# SPGSS2_1.0 register map
Vendor: Texas Instruments
Registers are 32-bit, read-write, no defined reset value unless marked. A register's access mark holds for its fields unless they carry their own. Offsets are as the file gives them; [hi:lo] are bit positions; lines under a group give offsets from that group; {n}, {i} and the like mark numbered series; 'fields as' and 'values as' point back to an identical list; <NAME> marks a mode.

## SPGSS2 (part 4 of 4)
0x47020 SPGSS2_UC3_I2CT_IPSTANDARD_CPU_INT group
  0x00 SPGSS2_UC3_I2CT_IPSTANDARD_IIDX ro — Interrupt index
    [7:0] STAT — I2C Module Interrupt Vector Value. This register provides the highes priority interrupt index. A read clears the corresponding interrupt flag in RIS and MISC. 15h-1Fh = Reserved
      0=NO_INTR (No interrupt pending); 1=RXDONEFG (Receive Done Flag); 2=TXDONEFG (Transmit Done Flag); 3=RXTRG (receive FIFO Trigger Level); 4=TXTRG (transmit FIFO Trigger level); 5=RXFULL (RX FIFO FULL Event/interrupt pending); 6=TXEMPTY (Transmit FIFO/Buffer Empty Event/interrupt pending); 7=TX_UNFL (Target TX FIFO underflow); 8=RX_OVFL (Target RX FIFO overflow event); 9=GENCALL (General Call Event); 10=STARTFG (Start Event); 11=STOPFG (Stop Event); 12=PEC_RX_ERR (PEC receive error event); 13=TIMEOUTA (Timeout A Event); 14=TIMEOUTB (Timeout B Event); 16=DMA_DONE_RX (DMA DONE on Channel RX); 17=DMA_DONE_TX (DMA DONE on Channel TX); 18=ARBLOSTFG (Arbitration Lost); 19=DMA_PREIRQ_RX (DMA PRE IRQ INTERRUPT); 20=DMA_PREIRQ_TX (DMA PRE IRQ INTERRUPT)
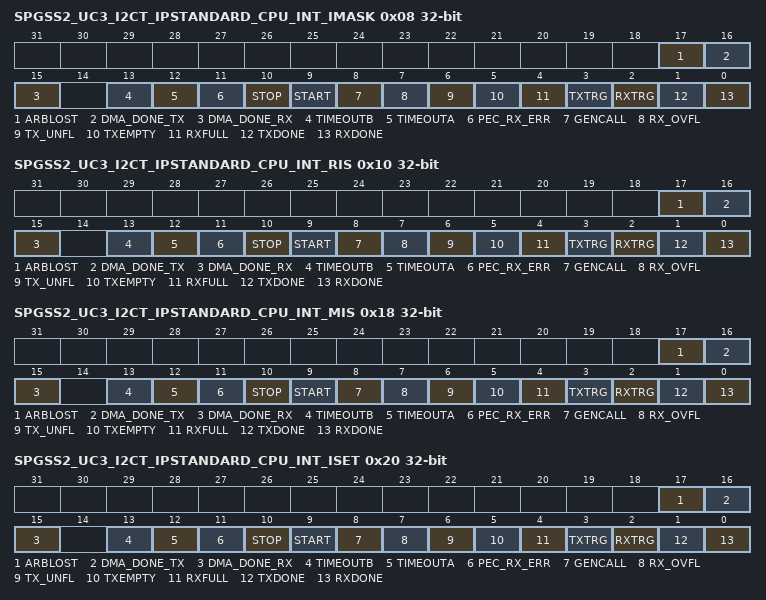
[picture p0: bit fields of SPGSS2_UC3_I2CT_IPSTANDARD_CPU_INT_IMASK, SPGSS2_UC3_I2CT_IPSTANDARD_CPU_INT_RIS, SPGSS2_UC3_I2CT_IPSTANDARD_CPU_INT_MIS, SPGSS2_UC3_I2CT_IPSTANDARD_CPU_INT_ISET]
  0x08 SPGSS2_UC3_I2CT_IPSTANDARD_CPU_INT_IMASK — Interrupt mask
    [all] fields
      0=CLR (Clear Interrupt Mask); 1=SET (Set Interrupt Mask)
    [17] ARBLOST — Arbitration Lost Interrupt
    [16] DMA_DONE_TX — DMA Done on Event Channel TX
    [15] DMA_DONE_RX — DMA Done on Event Channel RX
    [13] TIMEOUTB — Timeout B Interrupt
    [12] TIMEOUTA — Timeout A Interrupt
    [11] PEC_RX_ERR — RX Pec Error Interrupt
    [10] STOP — Stop Condition Interrupt
    [9] START — Start Condition Interrupt
    [8] GENCALL — General Call Interrupt
    [7] RX_OVFL — Target RX FIFO overflow
    [6] TX_UNFL — Target TX FIFO underflow
    [5] TXEMPTY — Target Transmit FIFO Empty interrupt mask. This interrupt is set if all data in the Transmit FIFO have been shifted out and the transmit goes into idle mode.
    [4] RXFULL — RXFIFO full event. This interrupt is set if an Target RX FIFO is full.
    [3] TXTRG — Transmit Trigger
    [2] RXTRG — Receive Trigger
    [1] TXDONE — Transmit Transaction completed Interrupt
    [0] RXDONE — Receive Data Interrupt Signals that a byte has been received
  0x10 SPGSS2_UC3_I2CT_IPSTANDARD_CPU_INT_RIS — Raw interrupt status
    [17] ARBLOST — Arbitration Lost Interrupt
      0=CLR (Interrupt did not occur); 1=SET (Set Interrupt Mask)
    [16] DMA_DONE_TX — DMA Done on Event Channel TX
      0=CLR (Clear interrupt); 1=SET (Set interrupt)
    [15] DMA_DONE_RX — DMA Done on Event Channel RX
      0=CLR (Clear interrupt); 1=SET (Set interrupt)
    [13] TIMEOUTB — Timeout B Interrupt
      0=CLR (Interrupt did not occur); 1=SET (Interrupt occured)
    [12] TIMEOUTA — Timeout A Interrupt
      0=CLR (Interrupt did not occur); 1=SET (Set Interrupt Mask)
    [11] PEC_RX_ERR — RX Pec Error Interrupt
      0=CLR (Interrupt did not occur); 1=SET (Interrupt ocuured)
    [10] STOP — Stop Condition Interrupt: set on a STOP condition if this target was being addressed
      0=CLR (Clear Interrupt); 1=SET (Interrupt is set when target is addressed and STOP condition is received)
    [9] START — Start Condition Interrupt: is set after a START condition is received and this target is addressed
      0=CLR (Clear interrupt); 1=SET (Set when a START condition is receivied and address matches target's address)
    [8] GENCALL — General Call Interrupt: set when a general call is received
      0=CLR (Clear Interrupt Mask); 1=SET (Set Interrupt Mask)
    [7] RX_OVFL — Receive FIFO overflow
      0=CLR (Interrupt did not occur); 1=SET (Interrupt Occured)
    [6] TX_UNFL — Transmit FIFO underflow
      0=CLR (Interrupt did not occur); 1=SET (Interrupt occured)
    [5] TXEMPTY — Transmit FIFO Empty Interrupt. This interrupt is set if all data in the Transmit FIFO have been shifted out and FSM goes into idle mode.
      0=CLR (Interrupt did not occur); 1=SET (Interrupt occured)
    [4] RXFULL — RXFIFO full event. This interrupt is set if an RX FIFO is full.
      0=CLR (Clear Interrupt Mask); 1=SET (Interrupt occured)
    [3] TXTRG — Transmit Trigger When FIFO is present, triggered as per IFLS settings When FIFO is not present, trigger when transmit buffer is empty
      0=CLR (Clear Interrupt Mask); 1=SET (Set Interrupt Mask)
    [2] RXTRG — Receive Trigger When FIFO is present, triggered as per IFLS settings when FIFO is not present, this indicates when buffer is full
      0=CLR (Clear Interrupt Mask); 1=SET (Set Interrupt Mask)
    [1] TXDONE — Transmission Done Interrupt: Set after a byte is transmitted
      0=CLR (Interrupt did not occur); 1=SET (Set Interrupt Mask)
    [0] RXDONE — Receive Done Interrupt: Set after a byte is received
      0=CLR (Interrupt did not occur); 1=SET (Set Interrupt Mask)
  0x18 SPGSS2_UC3_I2CT_IPSTANDARD_CPU_INT_MIS — Masked interrupt status
    [17] ARBLOST — Arbitration Lost Interrupt
      0=CLR (Interrupt did not occur); 1=SET (Set Interrupt Mask)
    [16] DMA_DONE_TX — DMA Done on Event Channel TX
      0=CLR (Clear MIS); 1=SET (Set MIS)
    [15] DMA_DONE_RX — DMA Done on Event Channel RX
      0=CLR (Clear MIS); 1=SET (Set MIS)
    [13] TIMEOUTB — Timeout B Interrupt
      0=CLR (Clear interrupt mask); 1=SET (Set interrupt mask)
    [12] TIMEOUTA — Timeout A Interrupt
      0=CLR (Interrupt did not occur); 1=SET (Set Interrupt Mask)
    [11] PEC_RX_ERR — Target RX Pec Error Interrupt
      0=CLR (Clear interrupt mask); 1=SET (Set interrupt mask)
    [10] STOP — STOP Detection Interrupt
      0=CLR (Clear MIS); 1=SET (Set MIS)
    [9] START — START Detection Interrupt
      0=CLR (Clear MIS); 1=SET (Set MIS)
    [8] GENCALL — General Call Interrupt
      0=CLR (Interrupt did not occur); 1=SET (Set Interrupt Mask)
    [7] RX_OVFL — Target RX FIFO overflow
      0=CLR (Clear interrupt mask); 1=SET (Set interrupt mask)
    [6] TX_UNFL — Target TX FIFO underflow
      0=CLR (Clear interrupt mask); 1=SET (Set interrupt mask)
    [5] TXEMPTY — Transmit FIFO Empty interrupt mask. This interrupt is set if all data in the Transmit FIFO have been shifted out and the transmit goes into idle mode.
      0=CLR (Interrupt did not occur); 1=SET (Interrupt occured)
    [4] RXFULL — RXFIFO full event. This interrupt is set if an RX FIFO is full.
      0=CLR (Clear Interrupt Mask); 1=SET (Interrupt occured)
    [3] TXTRG — Transmit Trigger
      0=CLR (Clear Interrupt Mask); 1=SET (Set Interrupt Mask)
    [2] RXTRG — Receive Trigger
      0=CLR (Clear Interrupt Mask); 1=SET (Set Interrupt Mask)
    [1] TXDONE — Transmit Transaction completed Interrupt
      0=CLR (Interrupt did not occur); 1=SET (Set Interrupt Mask)
    [0] RXDONE — Receive Data Interrupt Signals that a byte has been received
      0=CLR (Interrupt did not occur); 1=SET (Set Interrupt Mask)
  0x20 SPGSS2_UC3_I2CT_IPSTANDARD_CPU_INT_ISET — Interrupt set
    [17] ARBLOST — Arbitration Lost Interrupt
      0=NO_EFFECT (Writing 0 has no effect); 1=SET (Set Interrupt Mask)
    [16] DMA_DONE_TX — DMA Done on Event Channel TX
      0=NO_EFFECT (Writing 0 has no effect); 1=SET (Set interrupt)
    [15] DMA_DONE_RX — DMA Done on Event Channel RX
      0=NO_EFFECT (Writing 0 has no effect); 1=SET (Set interrupt)
    [13] TIMEOUTB — Timeout B Interrupt
      0=NO_EFFECT (Writing 0 has no effect); 1=SET (Set interrupt)
    [12] TIMEOUTA — Timeout A interrupt
      values as ARBLOST
    [11] PEC_RX_ERR — Target RX Pec Error Interrupt
      0=NO_EFFECT (Writing 0 has no effect); 1=SET (Set interrupt)
    [10] STOP — Stop Condition Interrupt
      0=NO_EFFECT (Writing 0 has no effect); 1=SET (Set interrupt)
    [9] START — Start Condition Interrupt
      0=NO_EFFECT (Writing 0 has no effect); 1=SET (Set interrupt)
    [8] GENCALL — General Call Interrupt
      values as ARBLOST
    [7] RX_OVFL — Target RX FIFO overflow
      0=NO_EFFECT (Writing 0 has no effect); 1=SET (Set interrupt)
    [6] TX_UNFL — Target TX FIFO underflow
      0=NO_EFFECT (Writing 0 has no effect); 1=SET (Set interrupt)
    [5] TXEMPTY — Transmit FIFO Empty interrupt mask. This interrupt is set if all data in the Transmit FIFO have been shifted out and the transmit goes into idle mode.
      0=NO_EFFECT (Writing 0 has no effect); 1=SET (Set Interrupt)
    [4] RXFULL — RXFIFO full event. This interrupt is set if an RX FIFO is full.
      0=NO_EFFECT (Clear Interrupt Mask); 1=SET (Set Interrupt)
    [3] TXTRG — Transmit Trigger
      0=NO_EFFECT (Clear Interrupt Mask); 1=SET (Set Interrupt Mask)
    [2] RXTRG — Receive Trigger
      values as TXTRG
    [1] TXDONE — Target Transmit Transaction completed Interrupt
      values as ARBLOST
    [0] RXDONE — Target Receive Data Interrupt Signals that a byte has been received
      values as ARBLOST
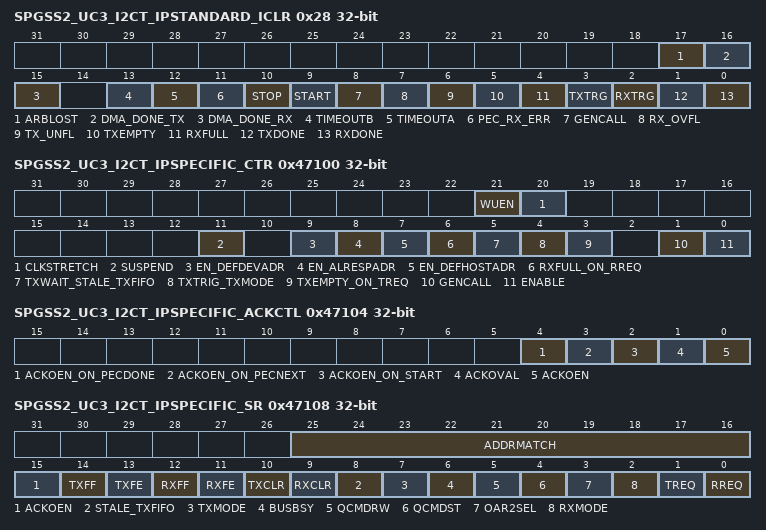
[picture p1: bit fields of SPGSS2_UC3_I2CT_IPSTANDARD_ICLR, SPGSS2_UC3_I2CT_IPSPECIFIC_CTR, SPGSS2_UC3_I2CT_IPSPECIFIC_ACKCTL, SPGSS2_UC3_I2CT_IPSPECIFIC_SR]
  0x28 SPGSS2_UC3_I2CT_IPSTANDARD_ICLR — Interrupt clear
    [17] ARBLOST — Arbitration Lost Interrupt
      0=NO_EFFECT (Writing 0 has no effect); 1=CLR (Set Interrupt Mask)
    [16] DMA_DONE_TX — DMA Done on Event Channel TX
      0=NO_EFFECT (Writing 0 has no effect); 1=CLR (Clear interrupt)
    [15] DMA_DONE_RX — DMA Done on Event Channel RX
      values as DMA_DONE_TX
    [13] TIMEOUTB — Timeout B Interrupt
      0=NO_EFFECT (Writing 0 has no effect); 1=CLR (Clear Interrupt)
    [12] TIMEOUTA — Timeout A interrupt
      values as ARBLOST
    [11] PEC_RX_ERR — Target RX Pec Error Interrupt
      values as TIMEOUTB
    [10] STOP — Target STOP Detection Interrupt
      values as DMA_DONE_TX
    [9] START — Target START Detection Interrupt
      values as DMA_DONE_TX
    [8] GENCALL — General Call Interrupt
      values as ARBLOST
    [7] RX_OVFL — Target RX FIFO overflow
      values as TIMEOUTB
    [6] TX_UNFL — Target TX FIFO underflow
      values as TIMEOUTB
    [5] TXEMPTY — Transmit FIFO Empty interrupt mask. This interrupt is set if all data in the Transmit FIFO have been shifted out and the transmit goes into idle mode.
      values as TIMEOUTB
    [4] RXFULL — RXFIFO full event. This interrupt is set if an RX FIFO is full.
      0=NO_EFFECT (Clear Interrupt Mask); 1=CLR (Clear Interrupt)
    [3] TXTRG — Transmit Trigger
      0=NO_EFFECT (Clear Interrupt Mask); 1=CLR (Set Interrupt Mask)
    [2] RXTRG — Receive Trigger
      values as TXTRG
    [1] TXDONE — Target Transmit Transaction completed Interrupt
      values as ARBLOST
    [0] RXDONE — Target Receive Data Interrupt Signals that a byte has been received
      values as ARBLOST
0x47100 SPGSS2_UC3_I2CT_IPSPECIFIC_CTR — I2C Target Control Register
  [21] WUEN — Target Wakeup Enable
    0=DISABLE (When 0, the Target is not allowed to clock stretch on START detection); 1=ENABLE (When 1, the Target is allowed to clock stretch on START detection and wait for faster clock to be abvailable. This allows clean wake up support for I2C in low power mode use cases)
  [20] CLKSTRETCH — Clock Stretch Enable
    0=DISABLE (clock stretching is disabled); 1=ENABLE (clock stretching is enabled)
  [11] SUSPEND — Suspend external communication
    0=DISABLE (Functional mode resumed); 1=ENABLE (External communication suspended)
  [9] EN_DEFDEVADR — Enable Default device address
    0=DISABLE (When this bit is 0, the default device address is not matched. NOTE: it may still be matched if programmed inside SOAR/SOAR2.); 1=ENABLE (When this bit is 1, default device address of 7h110_0001 is always matched by the Target address match logic.)
  [8] EN_ALRESPADR — Enable Alert Response Address
    0=DISABLE (When this bit is 0, the alert response address is not matched. NOTE: it may still be matched if programmed inside SOAR/SOAR2); 1=ENABLE (When this bit is 1, alert response address of 7h000_1100 is always matched by the Target address match logic.)
  [7] EN_DEFHOSTADR — Enable Default Host Address
    0=DISABLE (When this bit is 0, the default host address is not matched NOTE: it may still be matched if programmed inside SOAR/SOAR2); 1=ENABLE (When this bit is 1, default host address of 7h000_1000 is always matched by the Target address match logic.)
  [6] RXFULL_ON_RREQ — Rx full interrupt generated on RREQ condition as indicated in SSR
    0=DISABLE (When 0, RIS:SRXFULL will be set when only the Target RX FIFO is full. This allows the SRXFULL interrupt to be used to indicate that the I2C bus is being clock stretched and that the FW must either read the RX FIFO or ACK/NACK the current Rx byte.); 1=ENABLE (When 1, RIS:SRXFULL will be set when the Target State Machine is in the RX_WAIT or RX_ACK_WAIT states which occurs when the I2C transaction is clock stretched because the RX FIFO is full or the ACKOEN has been set and the state machine is waiting for FW to ACK/NACK the current byte.)
  [5] TXWAIT_STALE_TXFIFO — Tx transfer waits when stale data in Tx FIFO. This prevents stale bytes left in the TX FIFO from automatically being sent on the next I2C packet. Note: this should be used with TXEMPTY_ON_TREQ set to prevent the Target State Machine from waiting for TX FIFO data without an interrupt notification when the FIFO data is stale.
    0=DISABLE (When 0, the TX FIFO empty signal to the Target State Machine indicates that the TX FIFO is empty.); 1=ENABLE (When 1, the TX FIFO empty signal to the Target State Machine will indicate that the TX FIFO is empty or that the TX FIFO data is stale. The TX FIFO data is determined to be stale when there is data in the TX FIFO when the Target State Machine leaves the TXMODE as defined in the SSR register. This can occur is a Stop or timeout occur when there are bytes left in the TX FIFO.)
  [4] TXTRIG_TXMODE — Tx Trigger when Target FSM is in Tx Mode
    0=DISABLE (No special behavior); 1=ENABLE (When 1, RIS:TXTRG will be set when the Target TX FIFO has reached the trigger level AND the Target State Machine is in the TXMODE as defined in the SSR register. When cleared RIS:TXTRG will be set when the Target TX FIFO is at or above the trigger level. This setting can be used to hold off the TX DMA until a transaction starts. This allows the DMA to be configured when the I2C is idle but have it wait till the transaction starts to load the Target TX FIFO, so it can load from a memory buffer that might be changing over time.)
  [3] TXEMPTY_ON_TREQ — Tx Empty Interrupt on TREQ
    0=DISABLE (When 0, RIS:TXEMPTY will be set when only the Target TX FIFO is empty. This allows the TXEMPTY interrupt to be used to indicate that the I2C bus is being clock stretched and that Target TX data is required.); 1=ENABLE (When 1, RIS:TXEMPTY will be set when the Target State Machine is in the TX_WAIT state which occurs when the TX FIFO is empty AND the I2C transaction is clock stretched waiting for the FIFO to receive data.)
  [1] GENCALL — General call response enable Modify only when UCSWRST = 1. 0b = Do not respond to a general call 1b = Respond to a general call
    0=DISABLE (Do not respond to a general call); 1=ENABLE (Respond to a general call)
  [0] ENABLE — Setting this bit enables the module.
    0=DISABLE (Disables module operation.); 1=ENABLE (Enables module operation.)
0x47104 SPGSS2_UC3_I2CT_IPSPECIFIC_ACKCTL — I2C Target ACK Control
  [4] ACKOEN_ON_PECDONE — When set, this bit will automatically turn on target acknowledge enable field following the ACK/NACK of the received PEC byte. Status bit ACKOEN will reflect a value of '1' when automatic override enable is used.
    0=DISABLE (No special behavior); 1=ENABLE (When set this bit will automatically turn on the Target ACKOEN field following the ACK/NACK of the received PEC byte.)
  [3] ACKOEN_ON_PECNEXT — When set this bit will automatically turn on the Target acknowledge override following a ACK/NACK of the byte received just prior to the PEC byte. However, setting ACKCTL.ACKOEN bit will not automatically be ACKed/NACKed by the State Machine and firmware must perform this function by writing Target.ACKCTL register. Status bit ACKOEN will reflect a value of '1' when automatic override enable is used.
    0=DISABLE (No special behavior); 1=ENABLE (When set this bit will automatically turn on the Target ACKOEN field following the ACK/NACK of the byte received just prior to the PEC byte. Note that when ACKOEN is set the PEC byte will not automatically be ACKed/NACKed by the State Machine and FW must perform this function by writing Target_SACKCTL.)
  [2] ACKOEN_ON_START — When set this bit will automatically enable target override acknowlede following a Start Condition. Status bit ACKOEN will reflect a value of '1' when automatic override enable is used.
    0=DISABLE (No special behavior); 1=ENABLE (When set this bit will automatically turn on the Target ACKOEN field following a Start Condition.)
  [1] ACKOVAL — ACK Override Value Note: Override control is not applicable to Address frame. Bytes following address frame can be acknowledged using ACKOVAL.
    0=DISABLE (An ACK is sent indicating valid data or command.); 1=ENABLE (A NACK is sent indicating invalid data or command.)
  [0] ACKOEN — I2C Target ACK Override Enable Read SR.ACKOEN to check current status of this bit
    0=DISABLE (A response in not provided.); 1=ENABLE (An ACK or NACK is sent according to the value written to the ACKOVAL bit.)
0x47108 SPGSS2_UC3_I2CT_IPSPECIFIC_SR access per field — Status Register
  [25:16] ADDRMATCH rw — Indicates the address for which Target address match happened
    0=MINIMUM (Minimum Value); 0x3FF=MAXIMUM (Maximum Value)
  [15] ACKOEN ro — Status of ACK Override Enable
    0=DISABLE (ACK override is disabled); 1=ENABLE (ACK override was enabled in design)
  [14] TXFF ro — Transmit FIFO Full The meaning of this bit depends on the state of the FEN bit in the CTL0 register.
    0=CLEARED (The transmitter is not full.); 1=SET (If the FIFO is disabled (FEN is 0), the transmit holding register is full. If the FIFO is enabled (FEN is 1), the transmit FIFO is full.)
  [13] TXFE ro — Transmit FIFO Empty The meaning of this bit depends on the state of the FEN bit in the CTL0 register.
    0=CLEARED (The transmitter has data to transmit.); 1=SET (If the FIFO is disabled (FEN is 0), the transmit holding register is empty. If the FIFO is enabled (FEN is 1), the transmit FIFO is empty.)
  [12] RXFF ro — Receive FIFO Full The meaning of this bit depends on the state of the FEN bit in the CTL0 register.
    0=CLEARED (The receiver can receive data.); 1=SET (If the FIFO is disabled (FEN is 0), the receive holding register is full. If the FIFO is enabled (FEN is 1), the receive FIFO is full.)
  [11] RXFE ro — Receive FIFO Empty The meaning of this bit depends on the state of the FEN bit in the CTL0 register.
    0=CLEARED (The receiver is not empty.); 1=SET (If the FIFO is disabled (FEN is 0), the receive holding register is empty. If the FIFO is enabled (FEN is 1), the receive FIFO is empty.)
  [10] TXCLR ro — TX FIFO Clear Status
    0=CLEARED (FIFO is not cleared); 1=SET (FIFO clear is complete)
  [9] RXCLR ro — RX FIFO Clear Status
    values as TXCLR
  [8] STALE_TXFIFO rw
    0=CLEARED (Tx FIFO is not stale); 1=SET (The TX FIFO is stale. This occurs when the TX FIFO was not emptied during the previous I2C transaction.)
  [7] TXMODE rw — FSM is in TX MODE
    0=CLEARED (State Machine is not in TX_DATA, TX_WAIT, TX_ACK or ADDR_ACK state with the bus direction set to read.); 1=SET (State Machine is in TX_DATA, TX_WAIT, TX_ACK or ADDR_ACK state with the bus direction set to read.)
  [6] BUSBSY rw — I2C bus is busy
    0=CLEARED (The I2C Bus is not busy); 1=SET (The I2C Bus is busy. This is cleared on a timeout.)
  [5] QCMDRW ro — Quick Command Read / Write This bit only has meaning when the QCMDST bit is set. Value Description: 0: Quick command was a write 1: Quick command was a read
    0=CLEARED (Quick command was a write); 1=SET (Quick command was a read)
  [4] QCMDST ro — Quick Command Status Value Description: 0: The last transaction was a normal transaction or a transaction has not occurred. 1: The last transaction was a Quick Command transaction
    0=CLEARED (The last transaction was a normal transaction or a transaction has not occurred.); 1=SET (The last transaction was a Quick Command transaction.)
  [3] OAR2SEL ro — OAR2 Address Matched This bit gets reevaluated after every address comparison.
    0=CLEARED (Either the OAR2 address is not matched or the match is in legacy mode.); 1=SET (OAR2 address matched and ACKed by the Target.)
  [2] RXMODE rw — Target FSM is in Rx MODE
    0=CLEARED (The Target State Machine is not in the RX_DATA, RX_ACK, RX_WAIT, RX_ACK_WAIT or ADDR_ACK state with the bus direction set to write.); 1=SET (The Target State Machine is in the RX_DATA, RX_ACK, RX_WAIT, RX_ACK_WAIT or ADDR_ACK state with the bus direction set to write.)
  [1] TREQ ro — Transmit Request
    0=CLEARED (No outstanding transmit request.); 1=SET (I2C Target is addressed as a transmitter and is using clock stretching to delay the Controller until data has been written to the TXDATA FIFO (TX FIFO is empty).)
  [0] RREQ ro — Receive Request
    0=CLEARED (No outstanding receive data.); 1=SET (Module has outstanding receive data and is using clock stretching to delay the Controller until the data has been read from the RXDATA FIFO (RX FIFO is full).)
0x47118 SPGSS2_UC3_I2CT_IPSPECIFIC_GFCTL — I2C Glitch Filter Control
  [8] AGFEN — Analog Glitch Suppression Enable
    0=DISABLE (Analog Glitch Filter disable); 1=ENABLE (Analog Glitch Filter enable)
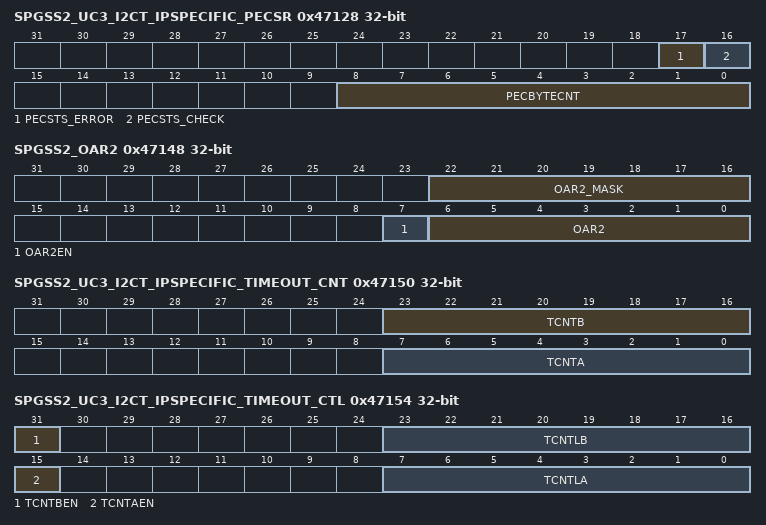
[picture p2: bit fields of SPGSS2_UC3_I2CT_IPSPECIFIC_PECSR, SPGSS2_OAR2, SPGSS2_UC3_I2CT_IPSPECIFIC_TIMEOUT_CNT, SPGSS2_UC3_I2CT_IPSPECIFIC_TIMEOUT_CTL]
0x47128 SPGSS2_UC3_I2CT_IPSPECIFIC_PECSR — PEC status register
  [17] PECSTS_ERROR — This status bit indicates if a PEC check error occurred in the transaction that occurred before the last Stop. Latched on Stop.
    0=CLEARED (Indicates PEC check error did not occurr in the transaction that occurred before the last Stop); 1=SET (Indicates PEC check error occurred in the transaction that occurred before the last Stop)
  [16] PECSTS_CHECK — This status bit indicates if the PEC was checked in the transaction that occurred before the last Stop. Latched on Stop.
    0=CLEARED (Indicates PEC was not checked in the transaction that occurred before the last Stop); 1=SET (Indicates PEC was checked in the transaction that occurred before the last Stop)
  [8:0] PECBYTECNT — This is the current PEC Byte Count of the State Machine.
    0=MINIMUM (Minimum Value); 0x1FF=MAXIMUM (Maximum Value)
0x47148 SPGSS2_OAR2 — Own Address 2
  [22:16] OAR2_MASK — Own Address 2 Mask: This field specifies bits A6 through A0 of the Target address. The bits with value 1 in SOAR2.OAR2_MASK field will make the corresponding incoming address bits to match by default regardless of the value inside SOAR2.OAR2 i.e. corresponding SOAR2.OAR2 bit is a dont care.
    0=MINIMUM (Minimum Value); 127=MAXIMUM (Maximum Value)
  [7] OAR2EN — Own Address 2 Enable
    0=DISABLE (The alternate address is disabled.); 1=ENABLE (Enables the use of the alternate address in the OAR2 field.)
  [6:0] OAR2 — Own Address 2This field specifies the alternate OAR2 address.
    0=MINIMUM (Smallest value); 127=MAXIMUM (Highest possible value)
0x47150 SPGSS2_UC3_I2CT_IPSPECIFIC_TIMEOUT_CNT access per field — I2C Timeout Count Register
  [23:16] TCNTB rw — Timeout Count B Current Count: This field contains the upper 8 bits of a 12-bit current counter for timeout counter B
    0=MINIMUM (Smallest Value); 255=MAXIMUM (Highest possible value)
  [7:0] TCNTA ro — Timeout Count A Current Count: This field contains the upper 8 bits of a 12-bit current counter for timeout counter A
    values as TCNTB
0x47154 SPGSS2_UC3_I2CT_IPSPECIFIC_TIMEOUT_CTL — I2C Timeout Count Control Register
  [31] TCNTBEN — Timeout Counter B Enable
    0=DISABLE (Disable Timeout Counter B); 1=ENABLE (Enable Timeout Counter B)
  [23:16] TCNTLB — Timeout Count B Load: Counter B is used for SCL High Detection. This field contains the upper 8 bits of a 12-bit pre-load value for the Timeout B count. NOTE: The value of CNTLB must be greater than 1h. Each count is equal to 1* clock period. For example, with 10MHz functional clock one timeout period will be equal to1*100ns.
    0=MINIMUM (Smallest possible value); 255=MAXIMUM (Highest possible value)
  [15] TCNTAEN — Timeout Counter A Enable
    values as TCNTBEN
  [7:0] TCNTLA — Timeout counter A load value Counter A is used for SCL low detection. This field contains the upper 8 bits of a 12-bit pre-load value for the Timeout A count. NOTE: The value of CNTLA must be greater than 1h. Each count is equal to 520 times the timeout period of functional clock. For example, with 8MHz functional clock and a 100KHz operating I2C clock, one timeout period will be equal to (1 / 8MHz) * 520 or 65 us.
    values as SPGSS2_UC3_I2CT_IPSPECIFIC_TIMEOUT_CNT.TCNTB
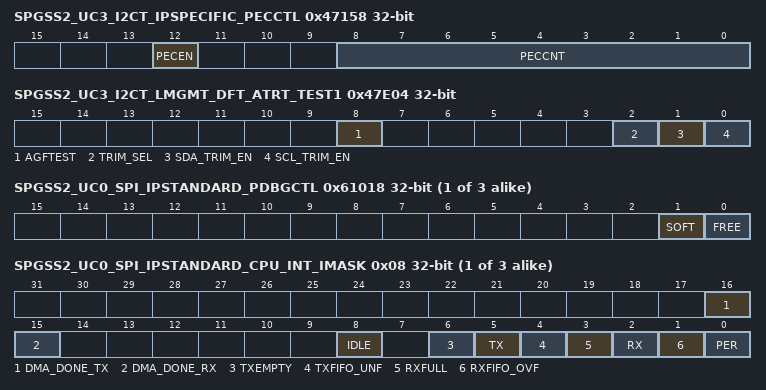
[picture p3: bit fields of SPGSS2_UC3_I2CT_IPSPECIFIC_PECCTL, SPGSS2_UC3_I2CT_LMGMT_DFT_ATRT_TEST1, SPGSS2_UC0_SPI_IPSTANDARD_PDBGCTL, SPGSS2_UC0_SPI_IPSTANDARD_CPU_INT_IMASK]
0x47158 SPGSS2_UC3_I2CT_IPSPECIFIC_PECCTL — I2C PEC control register
  [12] PECEN — PEC Enable This bit enables the SMB Packet Error Checking (PEC). When enabled the PEC is calculated on all bits except the Start, Stop, Ack and Nack. The PEC LSFR and the Byte Counter is set to 0 when the State Machine is in the IDLE state, which occur following a Stop or when a timeout occurs. The Counter is also set to 0 after the PEC byte is sent or received. Note that the NACK is automatically send following a PEC byte that results in a PEC error. The PEC Polynomial is x^8 + x^2 + x^1 + 1.
    0=DISABLE (PEC transmission and check is disabled); 1=ENABLE (PEC transmission and check is enabled)
  [8:0] PECCNT — When this field is non zero, the number of I2C data bytes are counted. When the byte count = PECCNT and the state machine is transmitting, the contents of the LSFR is loaded into the shift register instead of the byte received from the Tx FIFO. When the state machine is receiving, after the last bit of this byte is received the LSFR is checked and if it is non-zero, a PEC RX Error interrupt is generated. The I2C packet must be padded to include the PEC byte for both transmit and receive. In transmit mode the FIFO must be loaded with a dummy PEC byte. In receive mode the PEC byte will be passed to the Rx FIFO. In the normal use case, FW would set PECEN=1 and PECCNT=0 and use the ACKOEN until the remaining SMB packet length is known. FW would then set the PECCNT to the remaining packet length (Including PEC bye). FW would then configure DMA to allow the packet to complete unassisted and exit NoAck mode. Note that when the byte count = PEC CNT, the byte count is reset to 0 and multiple PEC calculation can automatically occur within a single I2C transaction
    0=MINIMUM (Minimum Value); 0x1FF=MAXIMUM (Maximum Value)
0x47E04 SPGSS2_UC3_I2CT_LMGMT_DFT_ATRT_TEST1 — Test 0 register
  [8] AGFTEST
  [2] TRIM_SEL — Select for which branch to trim
    0=FALLING_EDGE (Select Trim on falling edge); 1=RISING_EDGE (Select Trim on rising edge)
  [1] SDA_TRIM_EN — Analog glitch filter trimming enable for SDA
    0=DISABLE (Disable Trim for SDA); 1=ENABLE (Enable Trim for SDA)
  [0] SCL_TRIM_EN — Analog glitch filter trimming enable for SCL
    0=DISABLE (Disable Trim for SCL); 1=ENABLE (Enable Trim for SCL)
{0x61000+0x2000*i} SPGSS2_UC{i}_SPI_IPSTANDARD_CLKDIV (i=0..2) — Clock Divider
  [2:0] RATIO — Selects divide ratio of module clock
    0=DIV_BY_1 (Do not divide clock source); {v}=DIV_BY_{v+1} (Divide clock source by {v+1}) (v=1..7)
{0x61008+0x2000*i} SPGSS2_UC{i}_SPI_IPSTANDARD_CLKSEL (i=0..2) — Clock Select for Ultra Low Power peripherals
  [3] BUSCLK_SEL — Selects buscclk as clock source if enabled
    0=DISABLE (Does not select this clock as a source); 1=ENABLE (Select this clock as a source)
{0x61018+0x2000*i} SPGSS2_UC{i}_SPI_IPSTANDARD_PDBGCTL (i=0..2) — Peripheral Debug Control
  [1] SOFT — Soft halt boundary control. This function is only available, if [FREE] is set to 'STOP'
    0=DEPRECATED (Not supported); 1=DELAYED (The peripheral blocks the debug freeze until it has reached a boundary where it can resume without corruption)
  [0] FREE — Free run control
    0=STOP (The peripheral freezes functionality while the Core Halted input is asserted and resumes when it is deasserted.); 1=RUN (The peripheral ignores the state of the Core Halted input)
{0x61020+0x2000*i} SPGSS2_UC{i}_SPI_IPSTANDARD_CPU_INT group (i=0..2)
  0x00 SPGSS2_UC{i}_SPI_IPSTANDARD_IIDX ro — Interrupt Index Register
    [7:0] STAT — Interrupt index status
      0=NO_INTR (No interrupt pending); 1=PER_EVT (Transmit Parity Event/interrupt pending); 2=RXFIFO_OFV_EVT (RX FIFO Overflow Event/interrupt pending); 3=RX_EVT (Receive interrupt); 4=RXFULL_EVT (RX FIFO Full Interrupt); 5=TXFIFO_UNF_EVT (TX FIFO underflow interrupt); 6=TX_EVT (Transmit Event); 7=TX_EMPTY (Transmit Buffer Empty Event/interrupt pending); 9=IDLE_EVT (End of Transmit Event/interrupt pending); 10=RTOUT_EVT (SPI receive time-out interrupt); 16=DMA_DONE_RX (DMA DONE on RX); 17=DMA_DONE_TX (DMA DONE on TX); 19=DMA_PREIRQ_RX (DMA PRE IRQ RX INTERRUPT); 20=DMA_PREIRQ_TX (DMA PRE IRQ TX INTERRUPT); 21=LTOUT (SPI line time-out interrupt)
  0x08 SPGSS2_UC{i}_SPI_IPSTANDARD_CPU_INT_IMASK — Interrupt mask
    [16] DMA_DONE_TX — Enable DMA Done on TX Event Channel Interrupt
      0=CLR (Interrupt disabled); 1=SET (Set Interrupt Mask)
    [15] DMA_DONE_RX — Enable DMA Done on RX Event Channel Interrupt
      0=CLR (Interrupt disabled); 1=SET (Set Interrupt Mask)
    [8] IDLE — SPI Idle event mask.
      0=CLR (Clear Interrupt Mask); 1=SET (Set Interrupt Mask)
    [6] TXEMPTY — Transmit FIFO Empty event mask.
      0=CLR (Clear Interrupt Mask); 1=SET (Set Interrupt Mask)
    [5] TX — Mask Transmit Event
      0=CLR (Clear Interrupt Mask); 1=SET (Set Interrupt Mask)
    [4] TXFIFO_UNF — TX FIFO underflow interrupt mask
      0=CLR (Clear Interrupt Mask); 1=SET (Set Interrupt Mask)
    [3] RXFULL — RX FIFO Full Interrupt Mask
      0=CLR (Clear Interrupt Mask); 1=SET (Set Interrupt Mask)
    [2] RX — Mask Receive Event
      0=CLR (Clear Interrupt Mask); 1=SET (Set Interrupt Mask)
    [1] RXFIFO_OVF — RXFIFO overflow event mask.
      0=CLR (Clear Interrupt Mask); 1=SET (Set Interrupt Mask)
    [0] PER — Parity error event mask.
      0=CLR (Clear Interrupt Mask); 1=SET (Set Interrupt Mask)
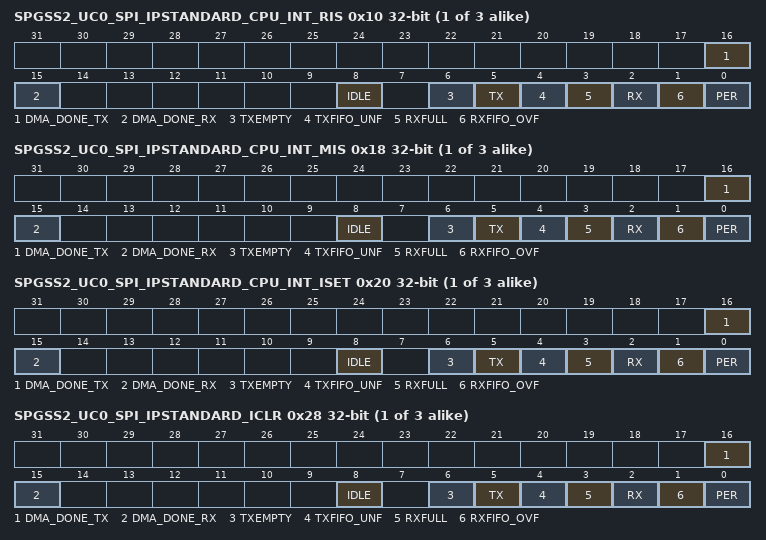
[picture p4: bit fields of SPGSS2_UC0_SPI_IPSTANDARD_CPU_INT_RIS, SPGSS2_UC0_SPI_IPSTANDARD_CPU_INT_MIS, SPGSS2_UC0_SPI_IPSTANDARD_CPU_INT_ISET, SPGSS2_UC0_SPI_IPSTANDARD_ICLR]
  0x10 SPGSS2_UC{i}_SPI_IPSTANDARD_CPU_INT_RIS — Raw interrupt status
    [16] DMA_DONE_TX — DMA Done on TX Event Channel Interrupt
      0=CLR (Interrupt disabled); 1=SET (Interrupt occured)
    [15] DMA_DONE_RX — DMA Done on RX Event Channel Interrupt
      0=CLR (Interrupt disabled); 1=SET (Interrupt occured)
    [8] IDLE — SPI has done finished transfers and changed into IDLE mode. This bit is set when BUSY goes low.
      0=CLR (Interrupt did not occur); 1=SET (Interrupt occurred)
    [6] TXEMPTY — Transmit FIFO Empty interrupt mask. This interrupt is set if all data in the Transmit FIFO have been move to the shift register.
      0=CLR (Interrupt did not occur); 1=SET (Interrupt occurred)
    [5] TX — Transmit event When FIFO is present, this bit is set when Tx FIFO threshold is reached When FIFO is not present, this bit is set when tx buffer is empty
      0=CLR (Interrupt did not occur); 1=SET (Interrupt occurred)
    [4] TXFIFO_UNF — TX FIFO Underflow Interrupt
      0=CLR (Interrupt did not occur); 1=SET (Interrupt occurred)
    [3] RXFULL — RX FIFO Full Interrupt
      0=CLR (Interrupt did not occur); 1=SET (Interrupt occurred)
    [2] RX — Receive event When FIFO is present, this bit is set when FIFO threshold is reached When FIFO is not present, this bit is set when a frame is received
      0=CLR (Interrupt did not occur); 1=SET (Interrupt occurred)
    [1] RXFIFO_OVF — RXFIFO overflow event. This interrupt is set if an RX FIFO overflow has been detected.
      0=CLR (Interrupt did not occur); 1=SET (Interrupt occurred)
    [0] PER — Parity error event: this bit is set if a Parity error has been detected
      0=CLR (Interrupt did not occur); 1=SET (Interrupt occurred)
  0x18 SPGSS2_UC{i}_SPI_IPSTANDARD_CPU_INT_MIS — Masked interrupt status
    [16] DMA_DONE_TX — Masked DMA Done on TX Event Channel Interrupt
      0=CLR (Interrupt did not occur); 1=SET (Interrupt occured)
    [15] DMA_DONE_RX — Masked DMA Done on RX Event Channel Interrupt
      0=CLR (Interrupt did not occur); 1=SET (Interrupt occured)
    [8] IDLE — Masked SPI IDLE mode event.
      0=CLR (Interrupt did not occur); 1=SET (Interrupt occurred)
    [6] TXEMPTY — Masked Transmit FIFO Empty event.
      0=CLR (Interrupt did not occur); 1=SET (Interrupt occurred)
    [5] TX — Masked Transmit FIFO event. This interrupt is set if the selected Transmit FIFO level has been reached.
      0=CLR (Interrupt did not occur); 1=SET (Interrupt occurred)
    [4] TXFIFO_UNF — TX FIFO underflow interrupt
      0=CLR (Interrupt did not occur); 1=SET (Interrupt occurred)
    [3] RXFULL — RX FIFO Full Interrupt
      0=CLR (Interrupt did not occur); 1=SET (Interrupt occurred)
    [2] RX — Masked Receive Event
      0=CLR (Interrupt did not occur); 1=SET (Interrupt occurred)
    [1] RXFIFO_OVF — Masked RXFIFO overflow event. This interrupt is set if an RX FIFO overflow has been detected.
      0=CLR (Interrupt did not occur); 1=SET (Interrupt occurred)
    [0] PER — Masked Parity error event: this bit if a Parity error has been detected
      0=CLR (Interrupt did not occur); 1=SET (Interrupt occurred)
  0x20 SPGSS2_UC{i}_SPI_IPSTANDARD_CPU_INT_ISET — Interrupt set
    [16] DMA_DONE_TX — Set DMA Done on TX Event Channel Interrupt
      0=NO_EFFECT (Interrupt disabled); 1=SET (Set Interrupt)
    [15] DMA_DONE_RX — Set DMA Done on RX Event Channel Interrupt
      0=NO_EFFECT (Interrupt disabled); 1=SET (Set Interrupt)
    [8] IDLE — Set SPI IDLE mode event.
      0=NO_EFFECT (Writing 0 has no effect); 1=SET (Set Interrupt)
    [6] TXEMPTY — Set Transmit FIFO Empty event.
      0=NO_EFFECT (Writing 0 has no effect); 1=SET (Set Interrupt)
    [5] TX — Set Transmit event.
      0=NO_EFFECT (Writing 0 has no effect); 1=SET (Set Interrupt)
    [4] TXFIFO_UNF — Set TX FIFO Underflow Event
      0=NO_EFFECT (Writing has no effect); 1=SET (Set interrupt)
    [3] RXFULL — Set RX FIFO Full Event
      0=NO_EFFECT (Writing has no effect); 1=SET (Set Interrupt)
    [2] RX — Set Receive event.
      0=NO_EFFECT (Writing 0 has no effect); 1=SET (Set Interrupt)
    [1] RXFIFO_OVF — Set RXFIFO overflow event.
      0=NO_EFFECT (Writing 0 has no effect); 1=SET (Set Interrupt)
    [0] PER — Set Parity error event.
      0=NO_EFFECT (Writing 0 has no effect); 1=SET (Set Interrupt)
  0x28 SPGSS2_UC{i}_SPI_IPSTANDARD_ICLR — Interrupt clear
    [16] DMA_DONE_TX — Clear DMA Done on TX Event Channel Interrupt
      0=NO_EFFECT (Interrupt disabled); 1=CLR (Clear Interrupt)
    [15] DMA_DONE_RX — Clear DMA Done on RX Event Channel Interrupt
      0=NO_EFFECT (Interrupt disabled); 1=CLR (Clear Interrupt)
    [8] IDLE — Clear SPI IDLE mode event.
      values as SPGSS2_UC3_I2CT_IPSTANDARD_CPU_INT.SPGSS2_UC3_I2CT_IPSTANDARD_ICLR.TIMEOUTB
    [6] TXEMPTY — Clear Transmit FIFO Empty event.
      values as SPGSS2_UC3_I2CT_IPSTANDARD_CPU_INT.SPGSS2_UC3_I2CT_IPSTANDARD_ICLR.TIMEOUTB
    [5] TX — Clear Transmit event.
      values as SPGSS2_UC3_I2CT_IPSTANDARD_CPU_INT.SPGSS2_UC3_I2CT_IPSTANDARD_ICLR.TIMEOUTB
    [4] TXFIFO_UNF — Clear TXFIFO underflow event
      0=NO_EFFECT (Writing has no effect); 1=CLR (Clear interrupt)
    [3] RXFULL — Clear RX FIFO underflow event
      0=NO_EFFECT (Writing has no effect); 1=CLR (Clear interrupt)
    [2] RX — Clear Receive event.
      values as SPGSS2_UC3_I2CT_IPSTANDARD_CPU_INT.SPGSS2_UC3_I2CT_IPSTANDARD_ICLR.TIMEOUTB
    [1] RXFIFO_OVF — Clear RXFIFO overflow event.
      values as SPGSS2_UC3_I2CT_IPSTANDARD_CPU_INT.SPGSS2_UC3_I2CT_IPSTANDARD_ICLR.TIMEOUTB
    [0] PER — Clear Parity error event.
      values as SPGSS2_UC3_I2CT_IPSTANDARD_CPU_INT.SPGSS2_UC3_I2CT_IPSTANDARD_ICLR.TIMEOUTB
{0x61050+0x2000*i} SPGSS2_UC{i}_SPI_IPSTANDARD_DMA_TRIG_RX group (i=0..2)
  0x08 SPGSS2_UC{i}_SPI_IPSTANDARD_DMA_TRIG_RX_IMASK — Interrupt mask
    [2] RX — Receive FIFO event mask.
      0=CLR (Clear Interrupt Mask); 1=SET (Set Interrupt Mask)
  0x10 SPGSS2_UC{i}_SPI_IPSTANDARD_DMA_TRIG_RX_RIS — Raw interrupt status
    [2] RX — Receive FIFO event.This interrupt is set if the selected Receive FIFO level has been reached
      0=CLR (Interrupt did not occur); 1=SET (Interrupt occurred)
  0x18 SPGSS2_UC{i}_SPI_IPSTANDARD_DMA_TRIG_RX_MIS — Masked interrupt status
    [2] RX — Receive FIFO event mask.
      0=CLR (Interrupt did not occur); 1=SET (Interrupt occurred)
  0x20 SPGSS2_UC{i}_SPI_IPSTANDARD_DMA_TRIG_RX_ISET — Interrupt set
    [2] RX — Set Receive FIFO event.
      0=NO_EFFECT (Writing 0 has no effect); 1=SET (Set Interrupt)
{0x61080+0x2000*i} SPGSS2_UC{i}_SPI_IPSTANDARD_DMA_TRIG_TX group (i=0..2)
  0x08 SPGSS2_UC{i}_SPI_IPSTANDARD_DMA_TRIG_TX_IMASK — Interrupt mask
    [5] TX — Transmit FIFO event mask.
      0=CLR (Clear Interrupt Mask); 1=SET (Set Interrupt Mask)
  0x10 SPGSS2_UC{i}_SPI_IPSTANDARD_DMA_TRIG_TX_RIS — Raw interrupt status
    [5] TX — Transmit FIFO event: A read returns the current mask for transmit FIFO interrupt. On a write of 1, the mask for transmit FIFO interrupt is set which means the interrupt state will be reflected in MIS.TXMIS. A write of 0 clears the mask which means MIS.TXMIS will not reflect the interrupt.
      0=CLR (Interrupt did not occur); 1=SET (Interrupt occurred)
  0x18 SPGSS2_UC{i}_SPI_IPSTANDARD_DMA_TRIG_TX_MIS — Masked interrupt status
    [5] TX — Masked Transmit FIFO event
      0=CLR (Interrupt did not occur); 1=SET (Interrupt occurred)
  0x20 SPGSS2_UC{i}_SPI_IPSTANDARD_DMA_TRIG_TX_ISET — Interrupt set
    [5] TX — Set Transmit FIFO event.
      0=NO_EFFECT (Writing 0 has no effect); 1=SET (Set Interrupt)
{0x610E4+0x2000*i} SPGSS2_UC{i}_SPI_IPSTANDARD_INTCTL (i=0..2) — Interrupt control register
  [0] INTEVAL — Writing a 1 to this field re-evaluates the interrupt sources.
    0=DISABLE (The interrupt or event line is disabled.); 1=EVAL (The interrupt or event line is in software mode. Software must clear the RIS.)
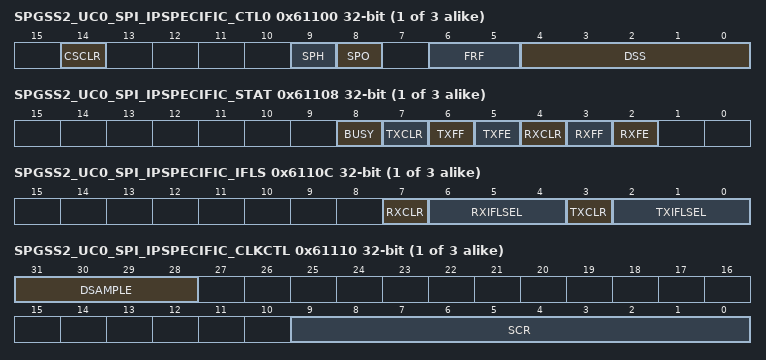
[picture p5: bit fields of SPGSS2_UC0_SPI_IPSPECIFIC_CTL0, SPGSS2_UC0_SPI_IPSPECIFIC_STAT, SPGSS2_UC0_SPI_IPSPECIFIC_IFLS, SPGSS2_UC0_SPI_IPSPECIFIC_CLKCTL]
{0x61100+0x2000*i} SPGSS2_UC{i}_SPI_IPSPECIFIC_CTL0 (i=0..2) — SPI control register 0
  [14] CSCLR — Clear shift register counter on CS inactive This bit is relevant only in the peripheral, CTL1.CP=0.
    0=DISABLE (Disable automatic clear of shift register when CS goes to disable.); 1=ENABLE (Enable automatic clear of shift register when CS goes to disable.)
  [9] SPH — CLKOUT phase (Motorola SPI frame format only) This bit selects the clock edge that captures data and enables it to change state. It has the most impact on the first bit transmitted by either permitting or not permitting a clock transition before the first data capture edge.
    0=FIRST (Data is captured on the first clock edge transition.); 1=SECOND (Data is captured on the second clock edge transition.)
  [8] SPO — CLKOUT polarity (Motorola SPI frame format only)
    0=LOW (SPI produces a steady state LOW value on the CLKOUT); 1=HIGH (SPI produces a steady state HIGH value on the CLKOUT)
  [6:5] FRF — Frame format Select
    0=MOTOROLA_3WIRE (Motorola SPI frame format (3 wire mode)); 1=MOTOROLA_4WIRE (Motorola SPI frame format (4 wire mode)); 2=TI_SYNC (TI synchronous serial frame format)
  [4:0] DSS — Data Size Select. Values 0 - 2 are reserved and shall not be used. 3h = 4_BIT : 4-bit data SPI allows only values up to 16 Bit
    {v}=Data Size Select bits: {v+1} (v=3..15)
{0x61108+0x2000*i} SPGSS2_UC{i}_SPI_IPSPECIFIC_STAT access per field (i=0..2) — Status Register
  [8] BUSY rw
    0=IDLE (SPI is in idle mode.); 1=ACTIVE (SPI is currently transmitting and/or receiving data)
  [7] TXCLR ro — TX FIFO Clear Status
    values as SPGSS2_UC3_I2CT_IPSPECIFIC_SR.TXCLR
  [6] TXFF ro — Transmit FIFO Full The meaning of this bit depends on the state of the FEN bit in the CTL0 register.
    values as SPGSS2_UC3_I2CT_IPSPECIFIC_SR.TXFF
  [5] TXFE rw — Transmit FIFO empty.
    0=NOT_EMPTY (Transmit FIFO is not empty.); 1=EMPTY (Transmit FIFO is empty.)
  [4] RXCLR ro — RX FIFO Clear Status
    values as SPGSS2_UC3_I2CT_IPSPECIFIC_SR.TXCLR
  [3] RXFF ro — Receive FIFO Full The meaning of this bit depends on the state of the FEN bit in the CTL0 register.
    values as SPGSS2_UC3_I2CT_IPSPECIFIC_SR.RXFF
  [2] RXFE rw — Receive FIFO empty.
    0=NOT_EMPTY (Receive FIFO is not empty.); 1=EMPTY (Receive FIFO is empty.)
{0x6110C+0x2000*i} SPGSS2_UC{i}_SPI_IPSPECIFIC_IFLS (i=0..2) — Interrupt FIFO Level Select Register
  [7] RXCLR — RX FIFO CLEAR. Setting this bit will clear the RX FIFO contents.
    0=DISABLE (Disable FIFO clear); 1=ENABLE (Enable FIFO Clear)
  [6:4] RXIFLSEL — FIFO Level Select for generating events (interrupt/dma). Note: for undefined settings the default configuration is used.
    1=LVL_1_4 (RX FIFO >= 1/4 full); 2=LVL_1_2 (RX FIFO >= 1/2 full (default)); 3=LVL_3_4 (RX FIFO >= 3/4 full); 4=LVL_NOT_EMPTY (Opposite of empty); 5=LVL_FULL (RX FIFO is full); 6=LVL_ALMOST_FULL (RX_FIFO >= (MAX_FIFO_LEN -1)); 7=LVL_ALMOST_EMPTY (RX_FIFO <= 1)
  [3] TXCLR — TX FIFO CLEAR. Setting this bit will clear the TX FIFO contents.
    0=DISABLE (Disable FIFO clear); 1=ENABLE (Enable FIFO Clear)
  [2:0] TXIFLSEL — FIFO Level Select for generating events (interrupt/dma). Note: for undefined settings the default configuration is used.
    1=LVL_3_4 (TX FIFO <= 3/4 empty); 2=LVL_1_2 (TX FIFO <= 1/2 empty (default)); 3=LVL_1_4 (TX FIFO <= 1/4 empty); 4=LVL_NOT_FULL (Opposite of full); 5=LVL_EMPTY (TX FIFO is empty); 6=LVL_ALMOST_EMPTY (TX FIFO <= 1); 7=LVL_ALMOST_FULL (TX_FIFO >= (MAX_FIFO_LEN -1))
{0x61110+0x2000*i} SPGSS2_UC{i}_SPI_IPSPECIFIC_CLKCTL (i=0..2) — Clock prescaler and divider register.
  [31:28] DSAMPLE — Delayed sampling value. In controller mode the data on the input pin will be delayed sampled by the defined clock cycles of internal functional clock hence relaxing the setup time of input data. This setting is useful in systems where the board delays and external peripheral delays are more than the input setup time of the controller. Please refer to the datasheet for values of controller input setup time and assess what DSAMPLE value meets the requirement of the system. Note: High values of DSAMPLE can cause HOLD time violations and must be factored in the calculations.
    0=MINIMUM (Smallest value); 15=MAXIMUM (Highest possible value)
  [9:0] SCR — Serial clock divider: This is used to generate the transmit and receive bit rate of the SPI. The SPI bit rate is (SPI's functional clock frequency)/((SCR+1)*2). SCR is a value from 0-1023.
    0=MINIMUM (Smallest value); 0x3FF=MAXIMUM (Highest possible value)
{0x61120+0x2000*i} SPGSS2_UC{i}_SPI_IPSPECIFIC_TXDATA (i=0..2) — TXDATA Register
  [15:0] DATA — Transmit Data When read, last written value will be returned. If the last write to this field was a 32-bit write (with PACKEN=1), 32-bits will be returned and if the last write was a 16-bit write (PACKEN=0), those 16-bits will be returned. When written, one or two FIFO entries will be written depending on PACKEN value. Data values are removed from the transmit FIFO one value at a time by the transmit logic. It is loaded into the transmit serial shifter, then serially shifted out onto the TXD output pin at the programmed bit rate. When a data size of less than 16 bits is selected, the user must right-justify data written to the transmit FIFO. The transmit logic ignores the unused bits.
{0x61124+0x2000*i} SPGSS2_UC{i}_SPI_IPSPECIFIC_RXDATA ro (i=0..2) — RXDATA Register
  [15:0] DATA — Received Data When PACKEN=1,two entries of the FIFO are returned as a 32-bit value. When PACKEN=0, 1 entry of FIFO is returned as 16-bit value. As data values are removed by the receive logic from the incoming data frame, they are placed into the entry in the receive FIFO, pointed to by the current FIFO write pointer. Received data less than 16 bits is automatically right justified in the receive buffer.
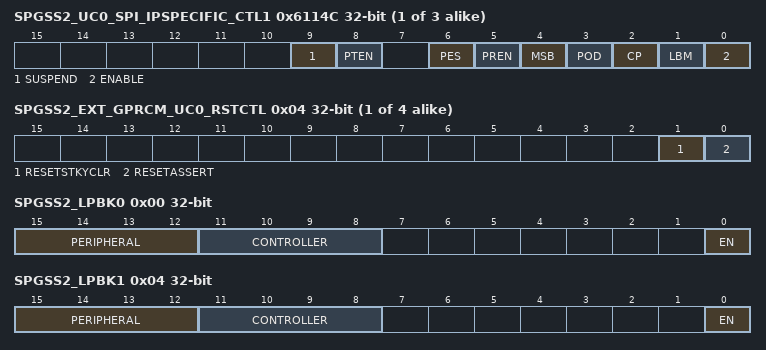
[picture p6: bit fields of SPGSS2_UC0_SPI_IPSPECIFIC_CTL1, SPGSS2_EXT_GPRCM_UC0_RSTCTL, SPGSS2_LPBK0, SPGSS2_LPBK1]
{0x6114C+0x2000*i} SPGSS2_UC{i}_SPI_IPSPECIFIC_CTL1 (i=0..2) — SPI control register 1
  [9] SUSPEND — Suspend external communication
    values as SPGSS2_UC3_I2CT_IPSPECIFIC_CTR.SUSPEND
  [8] PTEN — Parity transmit enable If enabled, parity transmission will be done for both controller and peripheral modes.
    0=DISABLE (Parity transmission is disabled); 1=ENABLE (Parity transmission is enabled)
  [6] PES — Even Parity Select
    0=DISABLE (Odd Parity mode); 1=ENABLE (Even Parity mode)
  [5] PREN — Parity receive enable If enabled, parity reception check will be done for both controller and peripheral modes In case of a parity miss-match the parity error flag RIS.PER will be set.
    0=DISABLE (Disable Parity receive function); 1=ENABLE (Enable Parity receive function)
  [4] MSB — MSB first select. Controls the direction of the receive and transmit shift register.
    0=DISABLE (LSB first); 1=ENABLE (MSB first)
  [3] POD — Peripheral-mode: Data output disabled This bit is relevant only in Peripheral mode. In multiple-peripheral system topologies, SPI controller can broadcast a message to all peripherals, while only one peripheral drives the line. POD can be used by the SPI peripheral to disable driving data on the line.
    0=DISABLE (SPI can drive the POCI output in peripheral mode.); 1=ENABLE (SPI cannot drive the POCI output in peripheral mode.)
  [2] CP — Controller or peripheral mode select. This bit can be modified only when SPI is disabled, CTL1.ENABLE=0.
    0=DISABLE (Select Peripheral mode); 1=ENABLE (Select Controller Mode)
  [1] LBM — Loop back mode
    0=DISABLE (Disable loopback mode); 1=ENABLE (Enable loopback mode)
  [0] ENABLE — SPI enable
    0=DISABLE (Disable module function); 1=ENABLE (Enable module function)
{0x61E00+0x2000*i} SPGSS2_UC{i}_SPI_LMGMT_DFT_ATRT_TEST0 (i=0..2) — Test 0 Register
  [3:0] DTB_MUX_SEL — This bit field is used to select DTB mux digital output signals.
    0=DISABLE (Disables DTB MUX); {v}=GRP{v} (Selects test group {v}) (v=1..9)
{0x80800+0x2000*i} SPGSS2_EXT_GPRCM_UC{i}_GPRCM group (i=0..3)
  0x00 SPGSS2_EXT_GPRCM_UC{i}_PWREN — Power enable
    [0] ENABLE — Enable the power
      0=DISABLE (Disable Power); 1=ENABLE (Enable Power)
  0x04 SPGSS2_EXT_GPRCM_UC{i}_RSTCTL — Reset Control
    [1] RESETSTKYCLR — Clear the RESETSTKY bit in the STAT register
      0=NOP (Writing 0 has no effect); 1=CLR (Clear reset sticky bit)
    [0] RESETASSERT — Assert reset to the peripheral
      0=NOP (Writing 0 has no effect); 1=ASSERT (Assert reset)
  0x08 SPGSS2_EXT_GPRCM_UC{i}_CLKCFG — Peripheral Clock Configuration Register
    [8] BLOCKASYNC — Async Clock Request is blocked from starting SYSOSC or forcing bus clock to 32MHz
      0=DISABLE (Not block async clock request); 1=ENABLE (Block async clock request)
  0x14 SPGSS2_EXT_GPRCM_UC{i}_GPRCM_STAT ro — Status Register
    [16] RESETSTKY — This bit indicates, if the peripheral was reset, since this bit was cleared by RESETSTKYCLR in the RSTCTL register
      0=NORES (The peripheral has not been reset since this bit was last cleared by RESETSTKYCLR in the RSTCTL register); 1=RESET (The peripheral was reset since the last bit clear)
{0x81100+0x2000*i} SPGSS2_UC{i}_IPSPECIFIC_IPMODE (i=0..3) — Mode Selection Register
  [1:0] SELECT — Free run control
    0=UART (Default functionality is UART); 1=SPI (SPG in SPI Mode); 2=I2C_CONTROLLER (SPG in I2C Controller Mode); 3=I2C_PERIPHERAL (SPG in I2C Peripheral Mode)
0xA0120 SPGSS2_UNICOMM_LPBK group
  0x00 SPGSS2_LPBK0 — Loopback between SPG instances User has to ensure that the SPGs looped back have the same underlying IP instantiated; i.e. both UART, both SPI, both I2C, etc.,
    [15:12] PERIPHERAL — Select SPG peripheral for loopback. Signals invovled in loopback based on interface chosen 1. SPI : CS, SCLK, SDI, SDO 2. I2C : SCL, SDA 3. UART : TX, RX
      {v}=SPG{v+1} (SPG responder select for loopback.) (v=0..15)
    [11:8] CONTROLLER — Select SPG controller for loopback. Signals invovled in loopback based on interface chosen 1. SPI : CS, SCLK, SDI, SDO 2. I2C : SCL, SDA 3. UART : TX, RX
      {v}=SPG{v+1} (SPG commander select for loopback.) (v=0..15)
    [0] EN — Loopback enable
      values as SPGSS2_UC0_SPI_IPSTANDARD_CLKSEL.BUSCLK_SEL
  0x04 SPGSS2_LPBK1 — Loopback between SPG instances User has to ensure that the SPGs looped back have the same underlying IP instantiated; i.e. both UART, both SPI, both I2C, etc.,
    fields as SPGSS2_UNICOMM_LPBK.SPGSS2_LPBK0
0xA01C0 SPGSS2_I2C_PAIR group
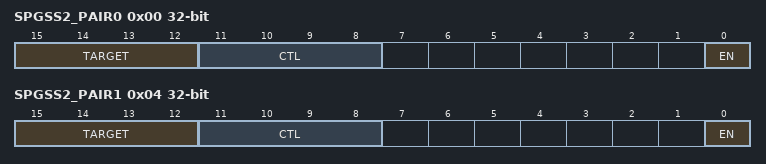
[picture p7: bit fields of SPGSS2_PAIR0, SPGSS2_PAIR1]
  0x00 SPGSS2_PAIR0 — Pairing of I2C for MULTI-MASTER/SMBUS applications
    [15:12] TARGET — UNICOMM instance for loopback. This instance will be treated as the target
      {v}=SPG{v+1} (SPG responder select for loopback.) (v=0..15)
    [11:8] CTL — UNICOMM instance for loopback. This instance will be treated as the controller.
      {v}=SPG{v+1} (SPG commander select for loopback.) (v=0..15)
    [0] EN — Enable
      values as SPGSS2_UC0_SPI_IPSTANDARD_CLKSEL.BUSCLK_SEL
  0x04 SPGSS2_PAIR1 — Pairing of I2C for MULTI-MASTER/SMBUS applications
    fields as SPGSS2_I2C_PAIR.SPGSS2_PAIR0
0xA0C00 SPGSS2_SPGSS_LMGMT_DFT_ATRT_TEST0 — Test 0 register
  [3:0] DTB_MUX_SEL — This bit field is used to select DTB mux digital output signals.
